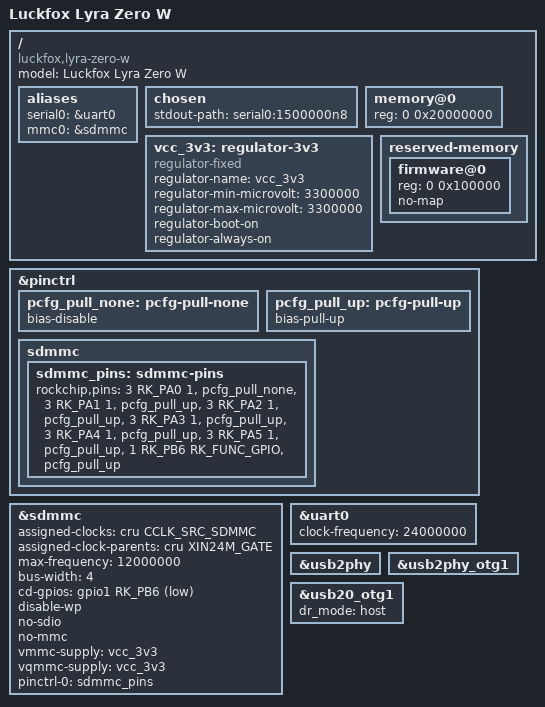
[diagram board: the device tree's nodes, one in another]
// SPDX-License-Identifier: (GPL-2.0+ OR MIT)
/*
 * Luckfox Lyra Zero W, U-Boot serial handoff.
 */

/dts-v1/;

#include <dt-bindings/gpio/gpio.h>
#include <dt-bindings/pinctrl/rockchip.h>
#include "rk3506.dtsi"
#include "rk3506-usb.dtsi"

/ {
	model = "Luckfox Lyra Zero W";
	compatible = "luckfox,lyra-zero-w", "rockchip,rk3506";

	aliases {
		serial0 = &uart0;
		mmc0 = &sdmmc;
	};

	chosen {
		stdout-path = "serial0:1500000n8";
	};

	memory@0 {
		device_type = "memory";
		reg = <0 0x20000000>;
	};

	vcc_3v3: regulator-3v3 {
		compatible = "regulator-fixed";
		regulator-name = "vcc_3v3";
		regulator-min-microvolt = <3300000>;
		regulator-max-microvolt = <3300000>;
		regulator-boot-on;
		regulator-always-on;
	};

	reserved-memory {
		#address-cells = <1>;
		#size-cells = <1>;
		ranges;

		/* The RK3506 U-Boot port reserves the first MiB for firmware. */
		firmware@0 {
			reg = <0 0x100000>;
			no-map;
		};
	};
};

&pinctrl {
	pcfg_pull_none: pcfg-pull-none {
		bias-disable;
	};

	pcfg_pull_up: pcfg-pull-up {
		bias-pull-up;
	};

	sdmmc {
		sdmmc_pins: sdmmc-pins {
			rockchip,pins = <3 RK_PA0 1 &pcfg_pull_none>,
					<3 RK_PA1 1 &pcfg_pull_up>,
					<3 RK_PA2 1 &pcfg_pull_up>,
					<3 RK_PA3 1 &pcfg_pull_up>,
					<3 RK_PA4 1 &pcfg_pull_up>,
					<3 RK_PA5 1 &pcfg_pull_up>,
					<1 RK_PB6 RK_FUNC_GPIO &pcfg_pull_up>;
		};
	};
};

&sdmmc {
	/* The CRU crystal path supplies up to 12 MHz at the card. */
	assigned-clocks = <&cru CCLK_SRC_SDMMC>;
	assigned-clock-parents = <&cru XIN24M_GATE>;
	max-frequency = <12000000>;
	bus-width = <4>;
	cd-gpios = <&gpio1 RK_PB6 GPIO_ACTIVE_LOW>;
	disable-wp;
	no-sdio;
	no-mmc;
	vmmc-supply = <&vcc_3v3>;
	vqmmc-supply = <&vcc_3v3>;
	pinctrl-names = "default";
	pinctrl-0 = <&sdmmc_pins>;
	status = "okay";
};

&uart0 {
	/* U-Boot leaves the 24 MHz baud clock and UART0 pins enabled. */
	clock-frequency = <24000000>;
	status = "okay";
};

&usb2phy {
	status = "okay";
};

&usb2phy_otg1 {
	status = "okay";
};

&usb20_otg1 {
	/* The onboard CH334F connects the radio and downstream ports. */
	dr_mode = "host";
	status = "okay";
};
